# Musca register map
Vendor: ARM Ltd.; Series: ARMv8-M Mainline; File version: 1.0
CPU: CM33 r0p1, little endian, MPU, no FPU, 3 interrupt priority bits, 8 SAU regions
Registers are 32-bit, read-write, reset 0x0 unless marked. A register's access mark holds for its fields unless they carry their own. Offsets are from the block's base; [hi:lo] are bit positions; {n}, {i} and the like mark numbered series.

## WATCHDOG — Non-secure Watchdog Timer
Base 0x40081000
Same registers: S32KWATCHDOG 0x4002E000, S32KWATCHDOG_Secure 0x5002E000, WATCHDOG_Secure 0x50081000
0x00 WDOGLOAD reset 0xFFFFFFFF — Watchdog Load Register
0x04 WDOGVALUE ro reset 0xFFFFFFFF — Watchdog Value Register
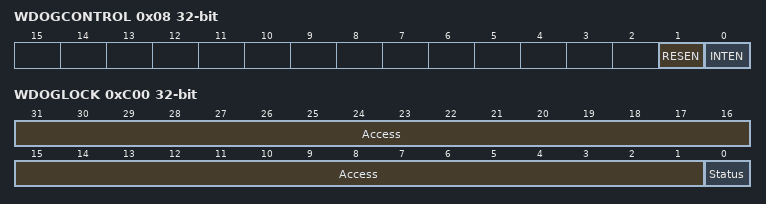
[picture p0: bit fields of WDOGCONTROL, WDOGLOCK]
0x08 WDOGCONTROL — Watchdog Control Register
  [1] RESEN — Enable watchdog reset output
    0=Disable Watchdog reset; 1=Enable Watchdog reset
  [0] INTEN — Enable the interrupt event
    0=Disable Watchdog interrupt; 1=Enable Watchdog interrupt
0x0C WDOGINTCLR wo — Watchdog Interrupt Clear Register
  [0] INT write-1-clears — Interrupt
0x10 WDOGRIS ro — Watchdog Raw Interrupt Status Register
  [0] RIS — Raw watchdog Interrupt
0x14 WDOGMIS ro — Watchdog Mask Interrupt Status Register
  [0] MIS — Masked Watchdog Interrupt
0xC00 WDOGLOCK — Watchdog Lock Register
  [31:1] Access — Enable register writes
  [0] Status — Register write enable status
    0=Enabled (Write access to all other registers is enabled. This is the default.); 1=Disabled (Write access to all other registers is disabled.)

## SPCTRL — Secure Privilege Control Block
Base 0x50080000
0x00 SPCSECTRL — Secure Privilege Controller Secure Configuration Control register
0x04 BUSWAIT — Bus Access wait control after reset
0x10 SECRESPCFG — Security Violation Response Configuration register
0x14 NSCCFG — Non Secure Callable Configuration for IDAU
0x1C SECMPCINTSTATUS ro — Secure MPC Interrupt Status
0x20 SECPPCINTSTAT ro — Secure PPC Interrupt Status
0x24 SECPPCINTCLR wo — Secure PPC Interrupt Clear
0x28 SECPPCINTEN — Secure PPC Interrupt Enable
0x30 SECMSCINTSTAT ro — Secure MSC Interrupt Status
0x34 SECMSCINTCLR — Secure MSC Interrupt Clear
0x38 SECMSCINTEN — Secure MSC Interrupt Enable
0x40 BRGINTSTAT ro — Bridge Buffer Error Interrupt Status
0x44 BRGINTCLR wo — Bridge Buffer Error Interrupt Clear
0x48 BRGINTEN — Bridge Buffer Error Interrupt Enable
0x50 AHBNSPPC0 — Non-Secure Access AHB slave Peripheral Protection Control 0
{0x60+4i} AHBNSPPCEXP{i} (i=0..3) — Expansion {i} Non_Secure Access AHB slave Peripheral Protection Control
0x70 APBNSPPC0 — Non-Secure Access APB slave Peripheral Protection Control 0
0x74 APBNSPPC1 — Non-Secure Access APB slave Peripheral Protection Control 1
{0x80+4i} APBNSPPCEXP{i} (i=0..3) — Expansion {i} Non_Secure Access APB slave Peripheral Protection Control
0x90 AHBSPPPC0 ro — Secure Unprivileged Access AHB slave Peripheral Protection Control 0
{0xA0+4i} AHBSPPPCEXP{i} (i=0..3) — Expansion {i} Secure Unprivileged Access AHB slave Peripheral Protection Control
0xB0 APBSPPPC0 — Secure Unprivileged Access APB slave Peripheral Protection Control 0
0xB4 APBSPPPC1 — Secure Unprivileged Access APB slave Peripheral Protection Control 1
{0xC0+4i} APBSPPPCEXP{i} (i=0..3) — Expansion {i} Secure Unprivileged Access APB slave Peripheral Protection Control
0xD0 NSMSCEXP ro — Expansion MSC Non-Secure Configuration
0xFD0 PID4 ro reset 0x4 — Peripheral ID 4
0xFE0 PID0 ro reset 0x52 — Peripheral ID 0
0xFE4 PID1 ro reset 0xB8 — Peripheral ID 1
0xFE8 PID2 ro reset 0xB — Peripheral ID 2
0xFEC PID3 ro — Peripheral ID 3
0xFF0 CIDR0 ro reset 0xD — Component ID 0
0xFF4 CIDR1 ro reset 0xF0 — Component ID 1
0xFF8 CIDR2 ro reset 0x5 — Component ID 2
0xFFC CIDR3 ro reset 0xB1 — Component ID 3

## NSPCTRL — Non-secure Privilege Control Block
Base 0x40080000
0x90 AHBNSPPPC0 — Non-Secure Unprivileged Access AHB slave Peripheral Protection Control #0
{0xA0+4i} AHBNSPPPCEXP{i} (i=0..3) — Expansion {i} Non_Secure Unprivileged Access AHB slave Peripheral Protection Control
0xB0 APBNSPPPC0 — Non-Secure Unprivileged Access APB slave Peripheral Protection Control 0
0xB4 APBNSPPPC1 — Non-Secure Unprivileged Access APB slave Peripheral Protection Control 1
{0xC0+4i} APBNSPPPCEXP{i} (i=0..3) — Expansion {i} Non_Secure Unprivileged Access APB slave Peripheral Protection Control
0xFD0 PIDR4 ro — Peripheral ID 4
0xFE0 PIDR0 ro reset 0x53 — Peripheral ID 0
0xFE4 PIDR1 ro reset 0xB8 — Peripheral ID 1
0xFE8 PIDR2 ro reset 0xB — Peripheral ID 2
0xFEC PIDR3 ro — Peripheral ID 3
0xFF0 CIDR0 ro reset 0xD — Component ID 0
0xFF4 CIDR1 ro reset 0xF0 — Component ID 1
0xFF8 CIDR2 ro reset 0x5 — Component ID 2
0xFFC CIDR3 ro reset 0xB1 — Component ID 3
